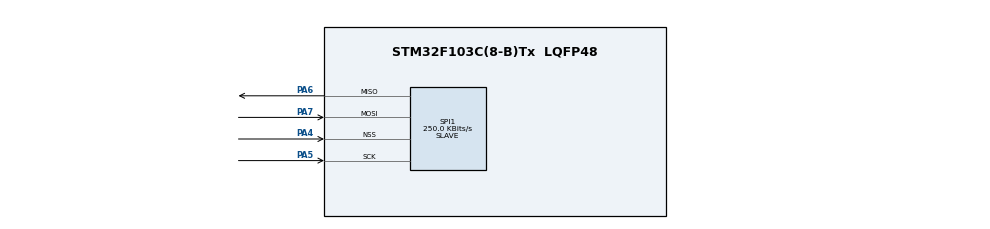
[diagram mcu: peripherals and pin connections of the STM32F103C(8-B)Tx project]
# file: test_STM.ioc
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Mcu.Family=STM32F1
Mcu.Name=STM32F103C(8-B)Tx
Mcu.Package=LQFP48
NVIC.PriorityGroup=NVIC_PRIORITYGROUP_4
NVIC.SPI1_IRQn=true\:0\:0\:false\:false\:true\:true
PA4.Mode=NSS_Signal_Hard_Input
PA4.Signal=SPI1_NSS
PA5.Mode=Full_Duplex_Slave
PA5.Signal=SPI1_SCK
PA6.Mode=Full_Duplex_Slave
PA6.Signal=SPI1_MISO
PA7.Mode=Full_Duplex_Slave
PA7.Signal=SPI1_MOSI
ProjectManager.HeapSize=0x200
ProjectManager.StackSize=0x400
ProjectManager.TargetToolchain=MDK-ARM V5
RCC.APB1Freq_Value=8000000
RCC.APB2Freq_Value=8000000
SPI1.BaudRatePrescaler=SPI_BAUDRATEPRESCALER_32
SPI1.CalculateBaudRate=250.0 KBits/s
SPI1.Direction=SPI_DIRECTION_2LINES
SPI1.Mode=SPI_MODE_SLAVE
SPI1.VirtualNSS=VM_NSSHARD
SPI1.VirtualType=VM_SLAVE
VP_SYS_VS_ND.Mode=No_Debug
board=test_STM

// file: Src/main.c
/**
  ******************************************************************************
  * @file           : main.c
  * @brief          : Main program body
  ******************************************************************************
  ** This notice applies to any and all portions of this file
  * that are not between comment pairs USER CODE BEGIN and
  * USER CODE END. Other portions of this file, whether
  * inserted by the user or by software development tools
  * are owned by their respective copyright owners.
  *
  * COPYRIGHT(c) 2018 STMicroelectronics
  *
  * Redistribution and use in source and binary forms, with or without modification,
  * are permitted provided that the following conditions are met:
  *   1. Redistributions of source code must retain the above copyright notice,
  *      this list of conditions and the following disclaimer.
  *   2. Redistributions in binary form must reproduce the above copyright notice,
  *      this list of conditions and the following disclaimer in the documentation
  *      and/or other materials provided with the distribution.
  *   3. Neither the name of STMicroelectronics nor the names of its contributors
  *      may be used to endorse or promote products derived from this software
  *      without specific prior written permission.
  *
  * THIS SOFTWARE IS PROVIDED BY THE COPYRIGHT HOLDERS AND CONTRIBUTORS "AS IS"
  * AND ANY EXPRESS OR IMPLIED WARRANTIES, INCLUDING, BUT NOT LIMITED TO, THE
  * IMPLIED WARRANTIES OF MERCHANTABILITY AND FITNESS FOR A PARTICULAR PURPOSE ARE
  * DISCLAIMED. IN NO EVENT SHALL THE COPYRIGHT HOLDER OR CONTRIBUTORS BE LIABLE
  * FOR ANY DIRECT, INDIRECT, INCIDENTAL, SPECIAL, EXEMPLARY, OR CONSEQUENTIAL
  * DAMAGES (INCLUDING, BUT NOT LIMITED TO, PROCUREMENT OF SUBSTITUTE GOODS OR
  * SERVICES; LOSS OF USE, DATA, OR PROFITS; OR BUSINESS INTERRUPTION) HOWEVER
  * CAUSED AND ON ANY THEORY OF LIABILITY, WHETHER IN CONTRACT, STRICT LIABILITY,
  * OR TORT (INCLUDING NEGLIGENCE OR OTHERWISE) ARISING IN ANY WAY OUT OF THE USE
  * OF THIS SOFTWARE, EVEN IF ADVISED OF THE POSSIBILITY OF SUCH DAMAGE.
  *
  ******************************************************************************
  */
#include "main.h"
#include "stm32f1xx_hal.h"

SPI_HandleTypeDef hspi1;

/* USER CODE BEGIN PV */
/* Private variables ---------------------------------------------------------*/
	uint8_t data_Rx[16];
	uint8_t data_Tx[16] = {1,2,3,3,4,5,5,5,5,15};
/* USER CODE END PV */

void SystemClock_Config(void);
static void MX_GPIO_Init(void);
static void MX_SPI1_Init(void);

/* USER CODE BEGIN PFP */
/* Private function prototypes -----------------------------------------------*/

/* USER CODE END PFP */

int main(void)
{

  /* MCU Configuration----------------------------------------------------------*/

  /* Reset of all peripherals, Initializes the Flash interface and the Systick. */
  HAL_Init();

  /* Configure the system clock */
  SystemClock_Config();

  /* Initialize all configured peripherals */
  MX_GPIO_Init();
  MX_SPI1_Init();
  /* USER CODE BEGIN 2 */
	HAL_SPI_Receive_IT(&hspi1,(uint8_t*)data_Rx,16);
  /* USER CODE END 2 */

  /* Infinite loop */
  while (1)
  {

  }

}

void SystemClock_Config(void)
{

  RCC_OscInitTypeDef RCC_OscInitStruct;
  RCC_ClkInitTypeDef RCC_ClkInitStruct;

    /**Initializes the CPU, AHB and APB busses clocks
    */
  RCC_OscInitStruct.OscillatorType = RCC_OSCILLATORTYPE_HSI;
  RCC_OscInitStruct.HSIState = RCC_HSI_ON;
  RCC_OscInitStruct.HSICalibrationValue = 16;
  RCC_OscInitStruct.PLL.PLLState = RCC_PLL_NONE;
  if (HAL_RCC_OscConfig(&RCC_OscInitStruct) != HAL_OK)
  {
    _Error_Handler(__FILE__, __LINE__);
  }

    /**Initializes the CPU, AHB and APB busses clocks
    */
  RCC_ClkInitStruct.ClockType = RCC_CLOCKTYPE_HCLK|RCC_CLOCKTYPE_SYSCLK
                              |RCC_CLOCKTYPE_PCLK1|RCC_CLOCKTYPE_PCLK2;
  RCC_ClkInitStruct.SYSCLKSource = RCC_SYSCLKSOURCE_HSI;
  RCC_ClkInitStruct.AHBCLKDivider = RCC_SYSCLK_DIV1;
  RCC_ClkInitStruct.APB1CLKDivider = RCC_HCLK_DIV1;
  RCC_ClkInitStruct.APB2CLKDivider = RCC_HCLK_DIV1;

  if (HAL_RCC_ClockConfig(&RCC_ClkInitStruct, FLASH_LATENCY_0) != HAL_OK)
  {
    _Error_Handler(__FILE__, __LINE__);
  }

    /**Configure the Systick interrupt time
    */
  HAL_SYSTICK_Config(HAL_RCC_GetHCLKFreq()/1000);

    /**Configure the Systick
    */
  HAL_SYSTICK_CLKSourceConfig(SYSTICK_CLKSOURCE_HCLK);

  /* SysTick_IRQn interrupt configuration */
  HAL_NVIC_SetPriority(SysTick_IRQn, 0, 0);
}

/* SPI1 init function */
static void MX_SPI1_Init(void)
{

  /* SPI1 parameter configuration*/
  hspi1.Instance = SPI1;
  hspi1.Init.Mode = SPI_MODE_SLAVE;
  hspi1.Init.Direction = SPI_DIRECTION_2LINES;
  hspi1.Init.DataSize = SPI_DATASIZE_8BIT;
  hspi1.Init.CLKPolarity = SPI_POLARITY_LOW;
  hspi1.Init.CLKPhase = SPI_PHASE_1EDGE;
  hspi1.Init.NSS = SPI_NSS_HARD_INPUT;
  hspi1.Init.BaudRatePrescaler = SPI_BAUDRATEPRESCALER_32;
  hspi1.Init.FirstBit = SPI_FIRSTBIT_MSB;
  hspi1.Init.TIMode = SPI_TIMODE_DISABLE;
  hspi1.Init.CRCCalculation = SPI_CRCCALCULATION_DISABLE;
  hspi1.Init.CRCPolynomial = 10;
  if (HAL_SPI_Init(&hspi1) != HAL_OK)
  {
    _Error_Handler(__FILE__, __LINE__);
  }

}

/** Pinout Configuration
*/
static void MX_GPIO_Init(void)
{

  /* GPIO Ports Clock Enable */
  __HAL_RCC_GPIOA_CLK_ENABLE();

}

void _Error_Handler(char *file, int line)
{
  while(1)
  {
  }
}

/************************ (C) COPYRIGHT STMicroelectronics *****END OF FILE****/
